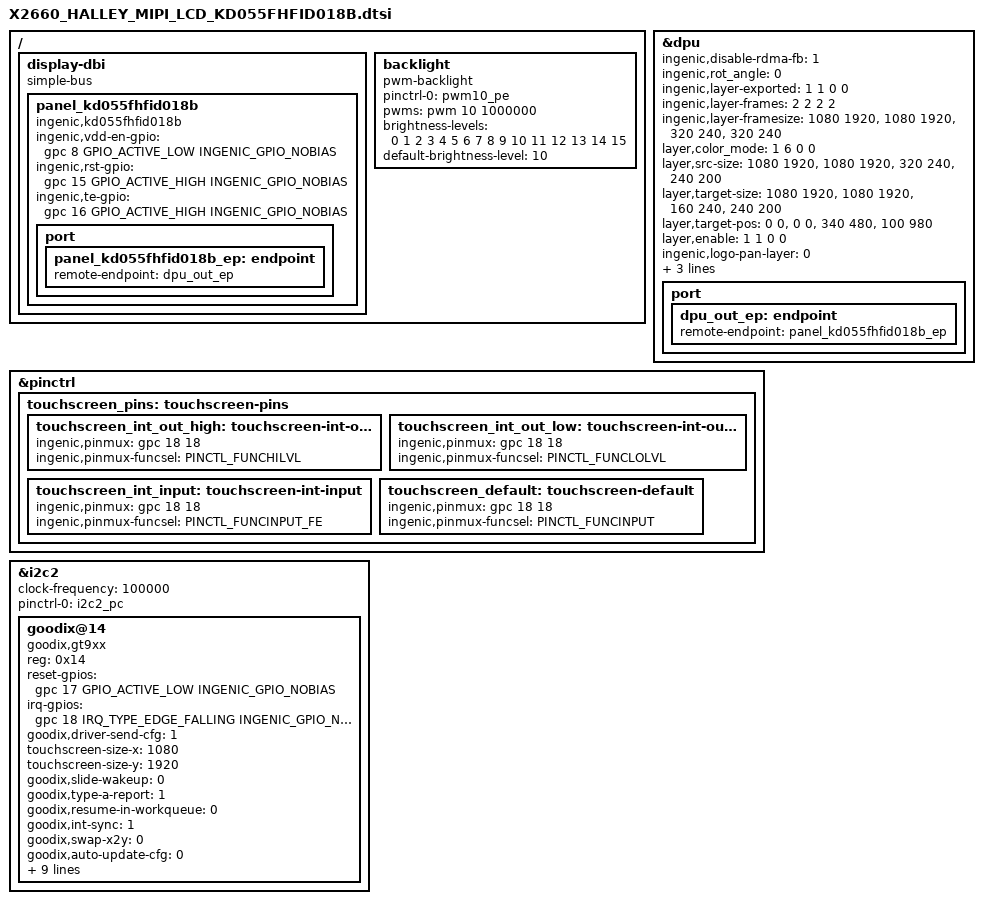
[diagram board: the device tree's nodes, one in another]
&dpu {
	status = "okay";
	ingenic,disable-rdma-fb = <1>;
	ingenic,rot_angle = <0>;
	/*Defines the init state of composer fb export infomations.*/
	ingenic,layer-exported = <1 1 0 0>;
	ingenic,layer-frames   = <2 2 2 2>;
	ingenic,layer-framesize = <1080 1920>, <1080 1920>, <320 240>, <320 240>;   /*Max framesize for each layer.*/
	layer,color_mode	= <1 6 0 0>;					/*src fmt,*/
	layer,src-size       	= <1080 1920>, <1080 1920>, <320 240>, <240 200>;	/*Layer src size should smaller than framesize*/
	layer,target-size	= <1080 1920>, <1080 1920>, <160 240>, <240 200>;	/*Target Size should smaller than src_size.*/
	layer,target-pos	= <0 0>, <0 0>, <340 480>, <100 980>;	/*target pos , the start point of the target panel.*/
	layer,enable		= <1 1 0 0>;					/*layer enabled or disabled.*/
	ingenic,logo-pan-layer	= <0>;						/*on which layer should init logo pan on.*/
    lane2_pn_swap;
    lane3_pn_swap;
	memory-region=<&reserved_memory>;
	port {
		dpu_out_ep: endpoint {
			remote-endpoint = <&panel_kd055fhfid018b_ep>;
	    };
	};
};

/ {
	display-dbi {
		compatible = "simple-bus";
		#interrupt-cells = <1>;
		#address-cells = <1>;
		#size-cells = <1>;
		ranges = <>;
		panel_kd055fhfid018b {
			compatible = "ingenic,kd055fhfid018b";
			status = "okay";
			pinctrl-names = "default";
			ingenic,vdd-en-gpio = <&gpc 8 GPIO_ACTIVE_LOW INGENIC_GPIO_NOBIAS>;
			ingenic,rst-gpio = <&gpc 15 GPIO_ACTIVE_HIGH INGENIC_GPIO_NOBIAS>;
            ingenic,te-gpio = <&gpc 16 GPIO_ACTIVE_HIGH INGENIC_GPIO_NOBIAS>;
			/*ingenic,lcd-pwm-gpio = <&gpe 2 GPIO_ACTIVE_HIGH INGENIC_GPIO_NOBIAS>;*/
			port {
				panel_kd055fhfid018b_ep: endpoint {
					remote-endpoint = <&dpu_out_ep>;
				};
			};
		};
	};

	backlight {
		compatible = "pwm-backlight";
	        pinctrl-names = "default";
    	        pinctrl-0 = <&pwm10_pe>;
		pwms = <&pwm 10 1000000>; /* arg1: pwm channel id [0~15]. arg2: period in ns. */
		brightness-levels = <0 1 2 3 4 5 6 7 8 9 10 11 12 13 14 15>;
		default-brightness-level = <10>;
	};

};

&pinctrl {
	touchscreen_pins:touchscreen-pins {
		touchscreen_int_out_high:touchscreen-int-out-high {
			ingenic,pinmux = <&gpc 18 18>;
			ingenic,pinmux-funcsel = <PINCTL_FUNCHILVL>;
		};
		touchscreen_int_out_low:touchscreen-int-out-low {
			ingenic,pinmux = <&gpc 18 18>;
			ingenic,pinmux-funcsel = <PINCTL_FUNCLOLVL>;
		};
		touchscreen_int_input:touchscreen-int-input {
			ingenic,pinmux = <&gpc 18 18>;
			ingenic,pinmux-funcsel = <PINCTL_FUNCINPUT_FE>;
		};
		touchscreen_default:touchscreen-default {
			ingenic,pinmux = <&gpc 18 18>;
			ingenic,pinmux-funcsel = <PINCTL_FUNCINPUT>;
		};
	};
};

&i2c2{
	status = "okay";
	clock-frequency = <100000>;
	pinctrl-names = "default";
	pinctrl-0 = <&i2c2_pc>;

	goodix@14{
		compatible = "goodix,gt9xx"; /* do not modify */
		reg = <0x14>; /* do not modify */
		reset-gpios = <&gpc 17 GPIO_ACTIVE_LOW INGENIC_GPIO_NOBIAS>; /* RST pin */
		irq-gpios = <&gpc 18 IRQ_TYPE_EDGE_FALLING INGENIC_GPIO_NOBIAS>; /* INT pin */
		goodix,driver-send-cfg = <1>;
		touchscreen-size-x = <1080>;
		touchscreen-size-y = <1920>;
		goodix,slide-wakeup = <0>;
		goodix,type-a-report = <1>;
		goodix,resume-in-workqueue = <0>;
		goodix,int-sync = <1>;
		goodix,swap-x2y = <0>;
		goodix,auto-update-cfg = <0>;
		goodix,power-off-sleep = <0>;
		goodix,pen-suppress-finger = <0>;
		irq-flags = <2>; /* 1 rising, 2 falling */
		pinctrl-names = "default", "int-output-high", "int-output-low", "int-input";
		pinctrl-0 = <&touchscreen_default>;
		pinctrl-1 = <&touchscreen_int_out_high>;
		pinctrl-2 = <&touchscreen_int_out_low>;
		pinctrl-3 = <&touchscreen_int_input>;
		goodix,cfg-group0 = [
                42  38  04  80  07  05  35  00  01  08  28  
                08  50  32  03  05  00  00  00  00  11  11  
                05  18  1A  1E  14  89  29  0C  3D  3F  0C  
                08  00  00  00  2A  02  2C  32  00  00  00  
                00  03  64  32  00  00  00  2D  5A  94  D5  
                02  00  00  00  04  8E  30  00  80  37  00  
                74  3F  00  69  49  00  60  54  00  60  00  
                00  00  00  00  00  00  00  00  00  00  00  
                00  00  00  00  00  00  00  00  00  00  00  
                00  00  00  00  00  00  00  00  00  00  00  
                00  00  18  16  14  12  10  0E  0C  0A  08  
                06  04  02  FF  FF  00  00  00  00  00  00  
                00  00  00  00  00  00  00  00  00  00  00  
                02  04  06  08  0A  0F  10  12  22  21  20  
                1F  1E  1D  1C  18  16  FF  FF  FF  FF  FF  
                FF  FF  FF  00  00  00  00  00  00  00  00  
                00  00  00  00  00  00  00  00  36  01   ];
        };
};

